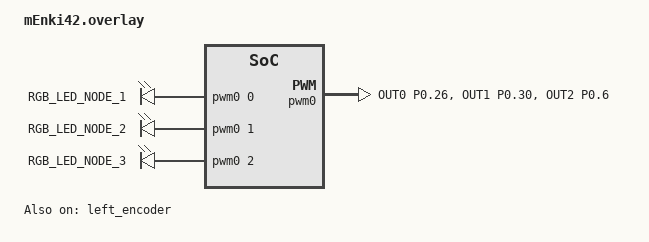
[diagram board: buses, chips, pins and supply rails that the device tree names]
/*
 * Copyright (c) 2020 The ZMK Contributors
 *
 * SPDX-License-Identifier: MIT
 */

#include "mEnki42.dtsi"
/ {
    backlight: pwmleds  {
		compatible = "pwm-leds";
		pwm_led_0: led_0  {
			pwms = <&pwm0 0 PWM_MSEC(10) PWM_POLARITY_INVERTED >;
            label = "RGB_LED_NODE_1";
		};
		pwm_led_1: led_1  {
			pwms = <&pwm0 1 PWM_MSEC(10) PWM_POLARITY_INVERTED >;
            label = "RGB_LED_NODE_2";
		};
		pwm_led_2: led_2  {
			pwms = <&pwm0 2 PWM_MSEC(10) PWM_POLARITY_INVERTED >;
            label = "RGB_LED_NODE_3";
		};
	};
};

&pwm0 {
    status = "okay";
    pinctrl-0 = <&pwm0_default>;
    pinctrl-1 = <&pwm0_sleep>;
    pinctrl-names = "default", "sleep";
};

&pinctrl {
    // Other Pinctrl definitions go here
    pwm0_default: pwm0_default {
        group1 {
            psels = <NRF_PSEL(PWM_OUT0, 0, 26)>,  // Red LED on P0.26
                    <NRF_PSEL(PWM_OUT1, 0, 30)>,  // Green LED on P0.30
                    <NRF_PSEL(PWM_OUT2, 0, 6)>;   // Blue LED on P0.06
        };
    };
    pwm0_sleep: pwm0_sleep {
        group1 {
            psels = <NRF_PSEL(PWM_OUT0, 0, 26)>,  // Red LED on P0.26
                    <NRF_PSEL(PWM_OUT1, 0, 30)>,  // Green LED on P0.30
                    <NRF_PSEL(PWM_OUT2, 0, 6)>;   // Blue LED on P0.06
            low-power-enable;
        };
    };
};

&left_encoder {
    status = "okay";
};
